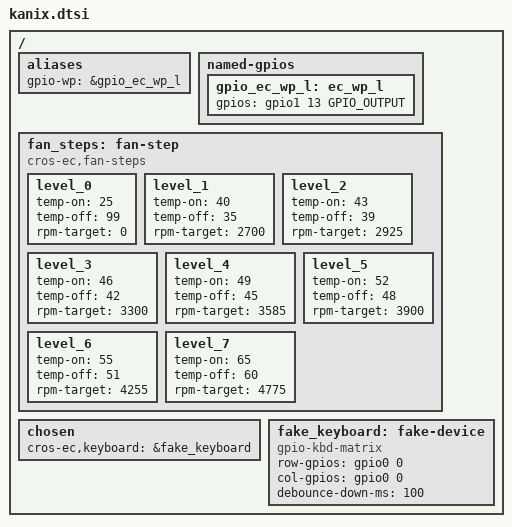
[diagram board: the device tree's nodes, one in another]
/* Copyright 2024 The ChromiumOS Authors
 * Use of this source code is governed by a BSD-style license that can be
 * found in the LICENSE file.
 */

#include "../native_sim.overlay"
#include "../../../../program/rex/kanix/cbi.dtsi"

#include <board-overlays/native_sim.dts>
#include <cros/binman.dtsi>
#include <cros/thermistor/thermistor.dtsi>
#include <dt-bindings/gpio_defines.h>
#include <dt-bindings/pwm/pwm.h>
#include <dt-bindings/wake_mask_event_defines.h>
#include <freq.h>


/ {
	aliases {
		gpio-wp = &gpio_ec_wp_l;
	};

	named-gpios {
		gpio_ec_wp_l: ec_wp_l {
			gpios = <&gpio1 13 GPIO_OUTPUT>;
		};
	};

	fan_steps: fan-step {
		compatible = "cros-ec,fan-steps";
		level_0 {
			temp-on = <25>;
			temp-off = <99>;
			rpm-target = <0>;
		};
		level_1 {
			temp-on = <40>;
			temp-off = <35>;
			rpm-target = <2700>;
		};
		level_2 {
			temp-on = <43>;
			temp-off = <39>;
			rpm-target = <2925>;
		};
		level_3 {
			temp-on = <46>;
			temp-off = <42>;
			rpm-target = <3300>;
		};
		level_4 {
			temp-on = <49>;
			temp-off = <45>;
			rpm-target = <3585>;
		};
		level_5 {
			temp-on = <52>;
			temp-off = <48>;
			rpm-target = <3900>;
		};
		level_6 {
			temp-on = <55>;
			temp-off = <51>;
			rpm-target = <4255>;
		};
		level_7 {
			temp-on = <65>;
			temp-off = <60>;
			rpm-target = <4775>;
		};
	};

	chosen {
		cros-ec,keyboard = &fake_keyboard;
	};

	fake_keyboard: fake-device {
		compatible = "gpio-kbd-matrix";
		row-gpios = <&gpio0 0 0>;
		col-gpios = <&gpio0 0 0>;
		debounce-down-ms = <100>;

		#include "../../../../program/rex/kanix/keyboard_set2.dtsi"
	};
};
